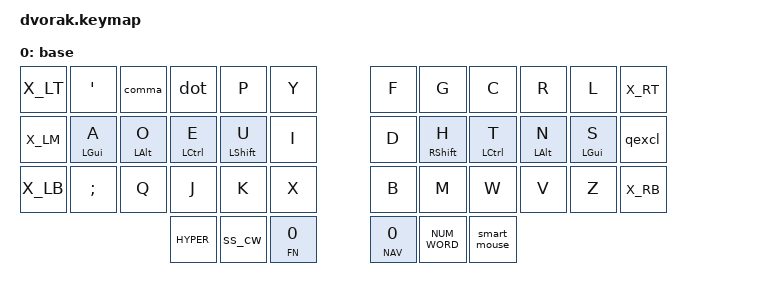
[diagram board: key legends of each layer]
ZMK_LAYER(base, // 0
//╭─────────────┬─────────────┬─────────────┬─────────────┬─────────────┬─────────────╮ ╭─────────────┬─────────────┬─────────────┬─────────────┬─────────────┬─────────────╮
    X_LT          &kp SQT       &kp comma     &kp dot       &kp P         &kp Y           &kp F         &kp G         &kp C         &kp R         &kp L         X_RT
//├─────────────┼─────────────┼─────────────┼─────────────┼─────────────┼─────────────┤ ├─────────────┼─────────────┼─────────────┼─────────────┼─────────────┴─────────────┤
    X_LM          &hml LGUI A   &hml LALT O   &hml LCTRL E  &hml LSHFT U  &kp I           &kp D         &hmr RSHFT H  &hmr LCTRL T  &hmr LALT N   &hmr LGUI S   &qexcl
//├─────────────┼─────────────┼─────────────┼─────────────┼─────────────┼─────────────┤ ├─────────────┼─────────────┼─────────────┼─────────────┼─────────────┴─────────────┤
    X_LB          &kp SEMI      &kp Q         &kp J         &kp K         &kp X           &kp B         &kp M         &kp W         &kp V         &kp Z         X_RB
//╰─────────────┴─────────────┴─────────────┼─────────────┼─────────────┼─────────────┤ ├─────────────┼─────────────┼─────────────┼─────────────┴─────────────┴─────────────╯
                                              HYPER         &ss_cw        &lt_bspc FN 0   &lt_spc NAV 0 NUM_WORD      &smart_mouse
//                                          ╰─────────────┴─────────────┴─────────────╯ ╰─────────────┴─────────────┴─────────────╯
)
